AUTOSAR XML (schema 4-2-1)
package /MyDataTypes
  base type myuint8: category=FIXED_LENGTH, base-type-size=8, base-type-encoding=NONE, native-declaration=unsigned char
  impl type myuint8: category=VALUE, base-type=myuint8, range phys 0..255, raw 0..255
package /Interfaces
  sender receiver interface IF_SR_DoorLock
    data DoorState: type=myuint8
  client server interface IF_CS_Led
    operation Led_Switch: possible-error=[E_OK, E_NOT_OK]
      arg Led_State: type=myuint8, direction=IN
    error E_OK: error-code=0
    error E_NOT_OK: error-code=1
package /SWCS
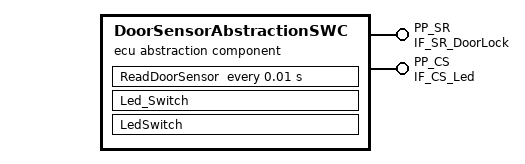
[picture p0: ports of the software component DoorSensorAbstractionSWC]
  ecu abstraction sw component type DoorSensorAbstractionSWC
    provide port PP_SR: provided-interface=IF_SR_DoorLock
    provide port PP_CS: provided-interface=IF_CS_Led
    behavior IB_DoorSensorAbstractionSWC
      timing event TE_10ms: start-on-event=ReadDoorSensor, period=0.01
      operation invoked event OIE_LedSwitch: start-on-event=Led_Switch, operation=PP_CS.Led_Switch
      runnable ReadDoorSensor: symbol=ReadDoorSensor_Runable
        data-write-access:
          access DA_DoorState: accessed-variable=PP_SR.DoorState
      runnable Led_Switch
      runnable LedSwitch: symbol=Led_Switch_Runable
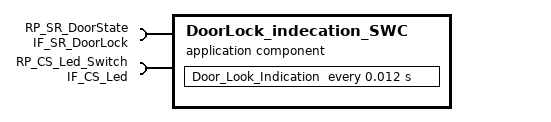
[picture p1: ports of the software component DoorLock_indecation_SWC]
  application sw component type DoorLock_indecation_SWC
    require port RP_SR_DoorState: required-interface=IF_SR_DoorLock
    require port RP_CS_Led_Switch: required-interface=IF_CS_Led
    behavior IB_DoorLock_indecation_SWC
      timing event TE_12ms: start-on-event=Door_Look_Indication, period=0.012
      runnable Door_Look_Indication: symbol=DoorLook_Indecation_runable
        data-read-access:
          access DA_read: accessed-variable=RP_SR_DoorState.DoorState
        sync call Server_Call: operation=RP_CS_Led_Switch.Led_Switch
package /Composition
  composition sw component type Composite_DoorLook_SWC
    component Door_Sensor_Abstract_SWC: type=DoorSensorAbstractionSWC
    component Door_Look_Indication_SWC: type=DoorLock_indecation_SWC
    connect Door_Sensor_Abstract_SWC.PP_SR -> Door_Look_Indication_SWC.RP_SR_DoorState
    connect Door_Sensor_Abstract_SWC.PP_CS -> Door_Look_Indication_SWC.RP_CS_Led_Switch
